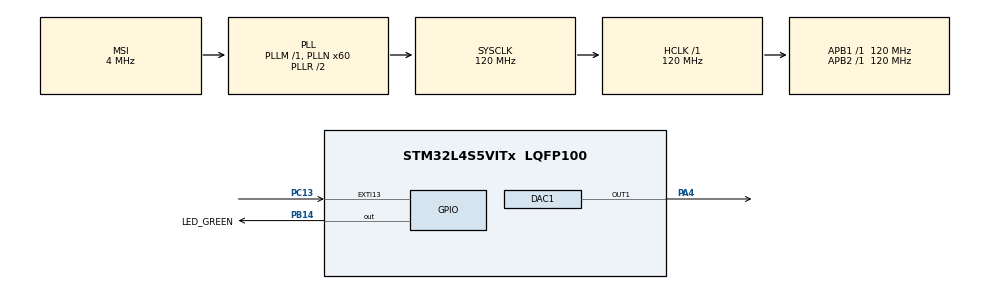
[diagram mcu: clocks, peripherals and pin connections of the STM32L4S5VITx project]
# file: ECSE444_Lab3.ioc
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DAC1.DAC_Trigger-DAC_OUT1=DAC_TRIGGER_T2_TRGO
Dma.DAC1_CH1.0.Direction=DMA_MEMORY_TO_PERIPH
Dma.DAC1_CH1.0.EventEnable=DISABLE
Dma.DAC1_CH1.0.Instance=DMA1_Channel1
Dma.DAC1_CH1.0.MemDataAlignment=DMA_MDATAALIGN_HALFWORD
Dma.DAC1_CH1.0.MemInc=DMA_MINC_ENABLE
Dma.DAC1_CH1.0.Mode=DMA_CIRCULAR
Dma.DAC1_CH1.0.PeriphDataAlignment=DMA_PDATAALIGN_HALFWORD
Dma.DAC1_CH1.0.PeriphInc=DMA_PINC_DISABLE
Dma.DAC1_CH1.0.Polarity=HAL_DMAMUX_REQUEST_GEN_RISING
Dma.DAC1_CH1.0.Priority=DMA_PRIORITY_LOW
Dma.DAC1_CH1.0.RequestNumber=1
Dma.DAC1_CH1.0.SignalID=NONE
Dma.DAC1_CH1.0.SyncEnable=DISABLE
Dma.DAC1_CH1.0.SyncPolarity=HAL_DMAMUX_SYNC_NO_EVENT
Dma.DAC1_CH1.0.SyncRequestNumber=1
Dma.DAC1_CH1.0.SyncSignalID=NONE
Dma.Request0=DAC1_CH1
Mcu.Family=STM32L4
Mcu.Name=STM32L4S5VITx
Mcu.Package=LQFP100
NVIC.DMA1_Channel1_IRQn=true\:0\:0\:false\:false\:true\:false\:true
NVIC.EXTI15_10_IRQn=true\:0\:0\:false\:false\:true\:true\:true
NVIC.PriorityGroup=NVIC_PRIORITYGROUP_4
NVIC.TIM2_IRQn=true\:0\:0\:false\:false\:true\:true\:true
PA13\ (JTMS/SWDIO).Signal=SYS_JTMS-SWDIO
PA4.Signal=COMP_DAC11_group
PB14.GPIO_Label=LED_GREEN
PB14.Signal=GPIO_Output
PB3\ (JTDO/TRACESWO).Signal=SYS_JTDO-SWO
PC13.Signal=GPXTI13
ProjectManager.HeapSize=0x200
ProjectManager.StackSize=0x400
ProjectManager.TargetToolchain=STM32CubeIDE
RCC.ADCFreq_Value=48000000
RCC.AHBFreq_Value=120000000
RCC.APB1Freq_Value=120000000
RCC.APB1TimFreq_Value=120000000
RCC.APB2Freq_Value=120000000
RCC.APB2TimFreq_Value=120000000
RCC.CortexFreq_Value=120000000
RCC.HCLKFreq_Value=120000000
RCC.HSE_VALUE=8000000
RCC.HSI48_VALUE=48000000
RCC.HSI_VALUE=16000000
RCC.LSE_VALUE=32768
RCC.MSI_VALUE=4000000
RCC.PLLN=60
RCC.PLLSAI1N=24
RCC.SYSCLKFreq_VALUE=120000000
RCC.SYSCLKSource=RCC_SYSCLKSOURCE_PLLCLK
RCC.USBFreq_Value=48000000
RCC.VCOOutputFreq_Value=240000000
SH.COMP_DAC11_group.0=DAC1_OUT1,DAC_OUT1
TIM2.Period=1813
TIM2.TIM_MasterOutputTrigger=TIM_TRGO_UPDATE
VP_TIM2_VS_ClockSourceINT.Mode=Internal
board=B-L4S5I-IOT01A

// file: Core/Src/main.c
/* USER CODE BEGIN Header */
/**
  ******************************************************************************
  * @file           : main.c
  * @brief          : Main program body
  ******************************************************************************
  * @attention
  *
  * <h2><center>&copy; Copyright (c) 2021 STMicroelectronics.
  * All rights reserved.</center></h2>
  *
  * This software component is licensed by ST under BSD 3-Clause license,
  * the "License"; You may not use this file except in compliance with the
  * License. You may obtain a copy of the License at:
  *                        opensource.org/licenses/BSD-3-Clause
  *
  ******************************************************************************
  */
/* USER CODE END Header */
#include "main.h"

/* USER CODE BEGIN Includes */
#include "arm_math.h"
#include "math.h"

/* USER CODE END Includes */

DAC_HandleTypeDef hdac1;
DMA_HandleTypeDef hdma_dac1_ch1;

TIM_HandleTypeDef htim2;

void SystemClock_Config(void);
static void MX_GPIO_Init(void);
static void MX_DMA_Init(void);
static void MX_DAC1_Init(void);
static void MX_TIM2_Init(void);

/* USER CODE BEGIN 0 */

uint8_t sineWave_1k[44]; // 1/sample * 44.1 kHz = 1000
uint8_t sineWave_middle[29]; // 29-> 1/sample * 44.1 kHz = 1.5kHz
uint8_t sineWave_2k[22]; // 22 samples -> 1/sample * 44.1 kHz = 2kHz

uint8_t sineWaveA;
uint8_t sineWaveB;
uint8_t sineWaveC;

uint8_t size1 = 44;
uint8_t size2 = 29;
uint8_t size3 = 22;

uint8_t state = 1;
int state2 = 1;
uint8_t nextDAC1 = 0;
uint8_t nextDAC2 = 0;
uint8_t nextDAC3 = 0;
uint8_t currVal;
uint8_t temp = 0;
uint8_t dacVal1;
uint8_t dacVal2;
uint8_t dacVal3;
uint8_t sineWaves[3];

float maxAmp = 55.0;

uint16_t saw;
uint16_t triangleWave;
int increment = 1;
int threshold = 255;
int threshold2 = 4095;
uint32_t delay = 0.25;
uint32_t timeS;
uint32_t deltaTimeS;
uint32_t timeT;
uint32_t deltaTimeT;
uint32_t timeW;
uint32_t deltaTimeW;
float Fs;
float Ft;
float Fw;
uint32_t currT;
int timePeriod = 1813;
int period_100 = 100 * 1813;
int period_200 = 200 * 1813;
int period_300 = 300 * 1813;
int period_400 = 400 * 1813;

//#define PART1
//#define DMAPLAY
#define TIMINT

void HAL_GPIO_EXTI_Callback(uint16_t GPIO_Pin){
		HAL_GPIO_TogglePin(LED_GREEN_GPIO_Port, LED_GREEN_Pin);
		HAL_DAC_Stop_DMA(&hdac1, DAC_CHANNEL_1);
		state += 1;
		if(state%4 == 1){ // fist sine wave from DMA
			HAL_DAC_Start_DMA(&hdac1, DAC_CHANNEL_1, (uint32_t*)sineWave_1k, size1, DAC_ALIGN_8B_R);
		}else if(state%4 == 2){ // second wave from DMA
			HAL_DAC_Start_DMA(&hdac1, DAC_CHANNEL_1, (uint32_t*)sineWave_middle, size2, DAC_ALIGN_8B_R);
		}else if(state%4 == 3){ //third sine wave set from DMA
			HAL_DAC_Start_DMA(&hdac1, DAC_CHANNEL_1, (uint32_t*)sineWave_2k, size3, DAC_ALIGN_8B_R);
		}
}

void HAL_TIM_PeriodElapsedCallback(TIM_HandleTypeDef *htim){
	// 80MHz/44.1 kHz  = 1813

	state2+=1;

	dacVal1 = sineWave_1k[nextDAC1];
	nextDAC1 = (nextDAC1+1)%size1;

	dacVal2 = sineWave_middle[nextDAC2];
	nextDAC2 = (nextDAC2+1)%size2;

	dacVal3 = sineWave_2k[nextDAC3];
	nextDAC3 = (nextDAC3+1)%size3;

	sineWaves[0] = dacVal1;
	sineWaves[1] = dacVal2;
	sineWaves[2] = dacVal3;

	if(state2 <period_100){
		temp =0;
	}
	else if (state2 >= period_100 && state2 <= period_200){
		temp = 1;
	}
	else if(state2 > period_200 && state2 <= period_300){
		temp = 2;
	}
	else if(state2 > period_300){
		state2 = 1;
	}
	//Not necessary
	if(temp >= 4){
		temp=0;
	}
	// -----
	HAL_DAC_SetValue(&hdac1, DAC1_CHANNEL_1, DAC_ALIGN_8B_R, sineWaves[temp]);
}

/* USER CODE END 0 */

int main(void)
{

  /* MCU Configuration--------------------------------------------------------*/

  /* Reset of all peripherals, Initializes the Flash interface and the Systick. */
   HAL_Init();

  /* Configure the system clock */
  SystemClock_Config();

  /* Initialize all configured peripherals */
  MX_GPIO_Init();
  MX_DMA_Init();
  MX_DAC1_Init();
  MX_TIM2_Init();
  /* USER CODE BEGIN 2 */

  //HAL_DAC_Start(&hdac1, DAC1_CHANNEL_2);

  /* USER CODE END 2 */

  /* Infinite loop */
  /* USER CODE BEGIN WHILE */

  //HAL_DAC_Start(&hdac1, DAC1_CHANNEL_2);

  float x = 0;

  int deltaS = (threshold2 + 1)/16;
  int deltaT = 2*deltaS;

  float sineWave;
  float angle1;
  float angle2;
  float angle3;
  uint32_t waitPeriod = 3000;

  for(int i = 0; i < size1; i++){
		  sineWave_1k[i] = maxAmp*(arm_sin_f32(angle1) + 1);
		  angle1 += (3.14*2)/size1;
  }
  for(int i = 0; i < size2; i++){
	  sineWave_middle[i] = maxAmp*(arm_sin_f32(angle2) + 1);
	  angle2 += (3.14*2)/size2;
  }
  for(int i = 0; i < size3; i++){
	  sineWave_2k[i] = maxAmp*(arm_sin_f32(angle3) + 1);
	  angle3 += (3.14*2)/size3;
  }

#ifdef TIMINT
  HAL_DAC_Start(&hdac1, DAC1_CHANNEL_1);
  HAL_TIM_Base_Start_IT(&htim2);
#endif

#ifdef DMAPLAY
  // FOR DMA SOUND PLAY
  HAL_TIM_Base_Start(&htim2);
  HAL_DAC_Start_DMA(&hdac1, DAC_CHANNEL_1, (uint32_t *)sineWave_1k, size1, DAC_ALIGN_8B_R);
#endif

  while (1)
  {

    /* USER CODE END WHILE */

    /* USER CODE BEGIN 3 */

#ifdef PART1

	  HAL_DAC_Start(&hdac1, DAC1_CHANNEL_1);

	  if(saw <= threshold2){
		  saw += deltaS;

	  } else {
		  saw = 0;
	  }
	  HAL_DAC_SetValue(&hdac1, DAC_CHANNEL_1, DAC_ALIGN_12B_R, saw);

	  if(increment && triangleWave >= threshold2){
		  increment =0;
	  } else if(increment){
		  triangleWave+=deltaT;
	  }else if(triangleWave == 0){
		  increment =1;
	  }else{
		  triangleWave-= deltaT;
	  }
	  //HAL_DAC_SetValue(&hdac1, DAC_CHANNEL_2, DAC_ALIGN_12B_R, triangleWave);
	  HAL_Delay(delay);

	  sineWave = (2047.5)*(1+arm_sin_f32(x));
	  // samples 0 -15 --> 16 --> (2*3.14)/16 = 0.3926
	  x += ((2*PI)/16);//0.3926; //(2*0.19634);
	  HAL_DAC_SetValue(&hdac1, DAC_CHANNEL_2, DAC_ALIGN_12B_R, (uint16_t)output);

#endif
  }
  /* USER CODE END 3 */
}

void SystemClock_Config(void)
{
  RCC_OscInitTypeDef RCC_OscInitStruct = {0};
  RCC_ClkInitTypeDef RCC_ClkInitStruct = {0};

  /** Configure the main internal regulator output voltage
  */
  if (HAL_PWREx_ControlVoltageScaling(PWR_REGULATOR_VOLTAGE_SCALE1_BOOST) != HAL_OK)
  {
    Error_Handler();
  }
  /** Initializes the RCC Oscillators according to the specified parameters
  * in the RCC_OscInitTypeDef structure.
  */
  RCC_OscInitStruct.OscillatorType = RCC_OSCILLATORTYPE_MSI;
  RCC_OscInitStruct.MSIState = RCC_MSI_ON;
  RCC_OscInitStruct.MSICalibrationValue = 0;
  RCC_OscInitStruct.MSIClockRange = RCC_MSIRANGE_6;
  RCC_OscInitStruct.PLL.PLLState = RCC_PLL_ON;
  RCC_OscInitStruct.PLL.PLLSource = RCC_PLLSOURCE_MSI;
  RCC_OscInitStruct.PLL.PLLM = 1;
  RCC_OscInitStruct.PLL.PLLN = 60;
  RCC_OscInitStruct.PLL.PLLP = RCC_PLLP_DIV2;
  RCC_OscInitStruct.PLL.PLLQ = RCC_PLLQ_DIV2;
  RCC_OscInitStruct.PLL.PLLR = RCC_PLLR_DIV2;
  if (HAL_RCC_OscConfig(&RCC_OscInitStruct) != HAL_OK)
  {
    Error_Handler();
  }
  /** Initializes the CPU, AHB and APB buses clocks
  */
  RCC_ClkInitStruct.ClockType = RCC_CLOCKTYPE_HCLK|RCC_CLOCKTYPE_SYSCLK
                              |RCC_CLOCKTYPE_PCLK1|RCC_CLOCKTYPE_PCLK2;
  RCC_ClkInitStruct.SYSCLKSource = RCC_SYSCLKSOURCE_PLLCLK;
  RCC_ClkInitStruct.AHBCLKDivider = RCC_SYSCLK_DIV1;
  RCC_ClkInitStruct.APB1CLKDivider = RCC_HCLK_DIV1;
  RCC_ClkInitStruct.APB2CLKDivider = RCC_HCLK_DIV1;

  if (HAL_RCC_ClockConfig(&RCC_ClkInitStruct, FLASH_LATENCY_5) != HAL_OK)
  {
    Error_Handler();
  }
}

static void MX_DAC1_Init(void)
{

  DAC_ChannelConfTypeDef sConfig = {0};

  /** DAC Initialization
  */
  hdac1.Instance = DAC1;
  if (HAL_DAC_Init(&hdac1) != HAL_OK)
  {
    Error_Handler();
  }
  /** DAC channel OUT1 config
  */
  sConfig.DAC_SampleAndHold = DAC_SAMPLEANDHOLD_DISABLE;
  sConfig.DAC_Trigger = DAC_TRIGGER_T2_TRGO;
  sConfig.DAC_HighFrequency = DAC_HIGH_FREQUENCY_INTERFACE_MODE_DISABLE;
  sConfig.DAC_OutputBuffer = DAC_OUTPUTBUFFER_ENABLE;
  sConfig.DAC_ConnectOnChipPeripheral = DAC_CHIPCONNECT_DISABLE;
  sConfig.DAC_UserTrimming = DAC_TRIMMING_FACTORY;
  if (HAL_DAC_ConfigChannel(&hdac1, &sConfig, DAC_CHANNEL_1) != HAL_OK)
  {
    Error_Handler();
  }

}

static void MX_TIM2_Init(void)
{

  TIM_ClockConfigTypeDef sClockSourceConfig = {0};
  TIM_MasterConfigTypeDef sMasterConfig = {0};

  htim2.Instance = TIM2;
  htim2.Init.Prescaler = 0;
  htim2.Init.CounterMode = TIM_COUNTERMODE_UP;
  htim2.Init.Period = 1813;
  htim2.Init.ClockDivision = TIM_CLOCKDIVISION_DIV1;
  htim2.Init.AutoReloadPreload = TIM_AUTORELOAD_PRELOAD_DISABLE;
  if (HAL_TIM_Base_Init(&htim2) != HAL_OK)
  {
    Error_Handler();
  }
  sClockSourceConfig.ClockSource = TIM_CLOCKSOURCE_INTERNAL;
  if (HAL_TIM_ConfigClockSource(&htim2, &sClockSourceConfig) != HAL_OK)
  {
    Error_Handler();
  }
  sMasterConfig.MasterOutputTrigger = TIM_TRGO_UPDATE;
  sMasterConfig.MasterSlaveMode = TIM_MASTERSLAVEMODE_DISABLE;
  if (HAL_TIMEx_MasterConfigSynchronization(&htim2, &sMasterConfig) != HAL_OK)
  {
    Error_Handler();
  }

}

static void MX_DMA_Init(void)
{

  /* DMA controller clock enable */
  __HAL_RCC_DMAMUX1_CLK_ENABLE();
  __HAL_RCC_DMA1_CLK_ENABLE();

  /* DMA interrupt init */
  /* DMA1_Channel1_IRQn interrupt configuration */
  HAL_NVIC_SetPriority(DMA1_Channel1_IRQn, 0, 0);
  HAL_NVIC_EnableIRQ(DMA1_Channel1_IRQn);

}

static void MX_GPIO_Init(void)
{
  GPIO_InitTypeDef GPIO_InitStruct = {0};

  /* GPIO Ports Clock Enable */
  __HAL_RCC_GPIOC_CLK_ENABLE();
  __HAL_RCC_GPIOA_CLK_ENABLE();
  __HAL_RCC_GPIOB_CLK_ENABLE();

  /*Configure GPIO pin Output Level */
  HAL_GPIO_WritePin(LED_GREEN_GPIO_Port, LED_GREEN_Pin, GPIO_PIN_RESET);

  /*Configure GPIO pin : PC13 */
  GPIO_InitStruct.Pin = GPIO_PIN_13;
  GPIO_InitStruct.Mode = GPIO_MODE_IT_RISING;
  GPIO_InitStruct.Pull = GPIO_NOPULL;
  HAL_GPIO_Init(GPIOC, &GPIO_InitStruct);

  /*Configure GPIO pin : LED_GREEN_Pin */
  GPIO_InitStruct.Pin = LED_GREEN_Pin;
  GPIO_InitStruct.Mode = GPIO_MODE_OUTPUT_PP;
  GPIO_InitStruct.Pull = GPIO_NOPULL;
  GPIO_InitStruct.Speed = GPIO_SPEED_FREQ_LOW;
  HAL_GPIO_Init(LED_GREEN_GPIO_Port, &GPIO_InitStruct);

  /* EXTI interrupt init*/
  HAL_NVIC_SetPriority(EXTI15_10_IRQn, 0, 0);
  HAL_NVIC_EnableIRQ(EXTI15_10_IRQn);

}

void Error_Handler(void)
{
  __disable_irq();
  while (1)
  {
  }
}

/************************ (C) COPYRIGHT STMicroelectronics *****END OF FILE****/
